# CY8C5888LTI_LP097 register map
File version: 0.1
CY8C58LP
Registers are 8-bit, read-write, no defined reset value unless marked. A register's access mark holds for its fields unless they carry their own. Offsets are from the block's base; lines under a group give offsets from that group; [hi:lo] are bit positions; {n}, {i} and the like mark numbered series; 'fields as' and 'values as' point back to an identical list; <NAME> marks a mode.

## Memory map
0x00000000 Counter_1
0x00000000 PWM_mots
0x00000000 Counter_2
0x00000000 Counter_4
0x00000000 Counter_3
0x00000000 PWM
0x00000000 UART
0x00000000 Trigger_out
0x00000000 Timer

## Counter_1
Base 0x00000000
0x4000640A Counter_1_COUNTER 16-bit — UDB.A0 - Current Counter Value
0x4000642A Counter_1_PERIOD 16-bit — UDB.D0 - Assigned Period
0x4000643A Counter_1_COMPARE 16-bit — UDB.D1 - Assigned Compare Value
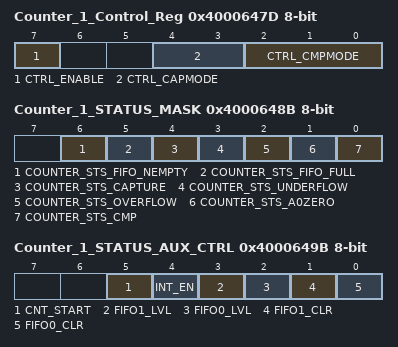
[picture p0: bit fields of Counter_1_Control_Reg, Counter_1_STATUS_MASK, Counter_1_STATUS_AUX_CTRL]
0x4000647D Counter_1_Control_Reg — UDB Control Register - Assigned Control Register Value
  [7] CTRL_ENABLE — Enable Counter
  [4:3] CTRL_CAPMODE — Capture mode
  [2:0] CTRL_CMPMODE — Compare mode
0x4000648B Counter_1_STATUS_MASK — UDB Status bits Interrupt Mask Enable Register
  [6] COUNTER_STS_FIFO_NEMPTY — FIFO Not Empty Status
  [5] COUNTER_STS_FIFO_FULL — FIFO Full Status
  [4] COUNTER_STS_CAPTURE — Capture Status
  [3] COUNTER_STS_UNDERFLOW — Underflow status
  [2] COUNTER_STS_OVERFLOW — Overflow status
  [1] COUNTER_STS_A0ZERO — A0 Zero ouput status
  [0] COUNTER_STS_CMP — Compare output status
0x4000649B Counter_1_STATUS_AUX_CTRL — UDB Auxilliary Control Register
  [5] CNT_START — FIFO0 clear
    0=E_CNT_START0 (Disable counter); 1=E_CNT_START1 (Enable counter)
  [4] INT_EN
    0=E_INT_EN0 (Interrupt disabled); 1=E_INT_EN1 (Interrupt enabled)
  [3] FIFO1_LVL — FIFO level
    0=E_FIFO_LVL_0 (FIFO LVL: input mode: FIFO not full; output mode: FIFO not empty); 1=E_FIFO_LVL_1 (FIFO LVL: input mode: FIFO at least 1/2 empty; output mode: FIFO at least 1/2 full)
  [2] FIFO0_LVL — FIFO level
    values as FIFO1_LVL
  [1] FIFO1_CLR — FIFO1 clear
    0=E_FIFO_CLR_0 (Normal FIFO operation); 1=E_FIFO_CLR_1 (Clear FIFO state)
  [0] FIFO0_CLR — FIFO0 clear
    values as FIFO1_CLR

## PWM_mots
Base 0x00000000
0x40006423 PWM_mots_COMPARE_Reg_ — UDB.D0 - Assigned Compare Value
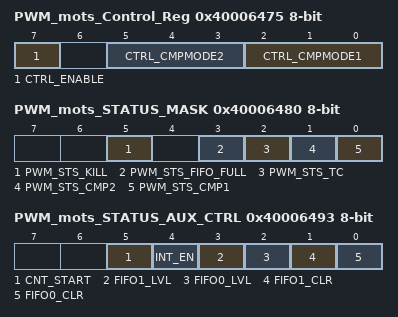
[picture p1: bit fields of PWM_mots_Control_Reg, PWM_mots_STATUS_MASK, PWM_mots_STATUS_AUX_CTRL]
0x40006475 PWM_mots_Control_Reg — UDB Control Register - Assigned Control Register Value
  [7] CTRL_ENABLE — Enable the PWM
  [5:3] CTRL_CMPMODE2 — Compare mode 2
  [2:0] CTRL_CMPMODE1 — Compare mode 1
0x40006480 PWM_mots_STATUS_MASK — UDB Status bits Interrupt Mask Enable Register
  [5] PWM_STS_KILL ro — Enables the Interrupt on Kill
  [3] PWM_STS_FIFO_FULL ro — FIFO Full Status Mask
  [2] PWM_STS_TC ro — Enables the Interrupt on Terminal Count
  [1] PWM_STS_CMP2 ro — Enables the Interrupt on Compare 2
  [0] PWM_STS_CMP1 ro — Enables the Interrupt on Compare 1
0x40006493 PWM_mots_STATUS_AUX_CTRL — UDB Auxilliary Control Register
  [5] CNT_START — FIFO0 clear
    0=E_CNT_START0 (Disable counter); 1=E_CNT_START1 (Enable counter)
  [4] INT_EN
    0=E_INT_EN0 (Interrupt disabled); 1=E_INT_EN1 (Interrupt enabled)
  [3] FIFO1_LVL — FIFO level
    0=E_FIFO_LVL_0 (FIFO LVL: input mode: FIFO not full; output mode: FIFO not empty); 1=E_FIFO_LVL_1 (FIFO LVL: input mode: FIFO at least 1/2 empty; output mode: FIFO at least 1/2 full)
  [2] FIFO0_LVL — FIFO level
    values as FIFO1_LVL
  [1] FIFO1_CLR — FIFO1 clear
    0=E_FIFO_CLR_0 (Normal FIFO operation); 1=E_FIFO_CLR_1 (Clear FIFO state)
  [0] FIFO0_CLR — FIFO0 clear
    values as FIFO1_CLR

## Counter_2
Base 0x00000000
0x4000640C Counter_2_COUNTER 16-bit — UDB.A0 - Current Counter Value
0x4000642C Counter_2_PERIOD 16-bit — UDB.D0 - Assigned Period
0x4000643C Counter_2_COMPARE 16-bit — UDB.D1 - Assigned Compare Value
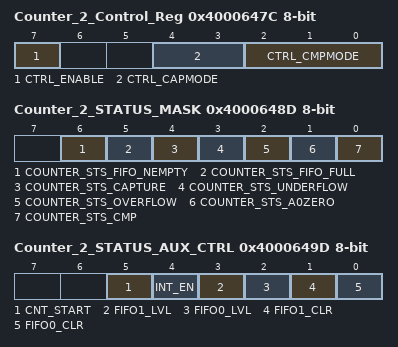
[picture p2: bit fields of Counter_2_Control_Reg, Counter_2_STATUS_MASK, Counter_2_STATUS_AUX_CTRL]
0x4000647C Counter_2_Control_Reg — UDB Control Register - Assigned Control Register Value
  [7] CTRL_ENABLE — Enable Counter
  [4:3] CTRL_CAPMODE — Capture mode
  [2:0] CTRL_CMPMODE — Compare mode
0x4000648D Counter_2_STATUS_MASK — UDB Status bits Interrupt Mask Enable Register
  [6] COUNTER_STS_FIFO_NEMPTY — FIFO Not Empty Status
  [5] COUNTER_STS_FIFO_FULL — FIFO Full Status
  [4] COUNTER_STS_CAPTURE — Capture Status
  [3] COUNTER_STS_UNDERFLOW — Underflow status
  [2] COUNTER_STS_OVERFLOW — Overflow status
  [1] COUNTER_STS_A0ZERO — A0 Zero ouput status
  [0] COUNTER_STS_CMP — Compare output status
0x4000649D Counter_2_STATUS_AUX_CTRL — UDB Auxilliary Control Register
  [5] CNT_START — FIFO0 clear
    0=E_CNT_START0 (Disable counter); 1=E_CNT_START1 (Enable counter)
  [4] INT_EN
    0=E_INT_EN0 (Interrupt disabled); 1=E_INT_EN1 (Interrupt enabled)
  [3] FIFO1_LVL — FIFO level
    0=E_FIFO_LVL_0 (FIFO LVL: input mode: FIFO not full; output mode: FIFO not empty); 1=E_FIFO_LVL_1 (FIFO LVL: input mode: FIFO at least 1/2 empty; output mode: FIFO at least 1/2 full)
  [2] FIFO0_LVL — FIFO level
    values as FIFO1_LVL
  [1] FIFO1_CLR — FIFO1 clear
    0=E_FIFO_CLR_0 (Normal FIFO operation); 1=E_FIFO_CLR_1 (Clear FIFO state)
  [0] FIFO0_CLR — FIFO0 clear
    values as FIFO1_CLR
